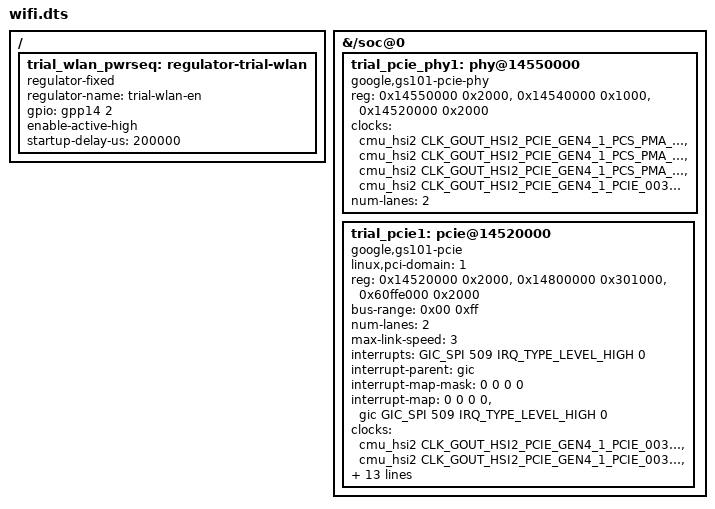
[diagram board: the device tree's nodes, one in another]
// SPDX-License-Identifier: GPL-2.0-only
// PCIe1 enumeration trial; reboot-only DT lifetime, no WiFi endpoint driver.
// Derived from M8 commit850061c7 and checked against stock CP1A.260305.018.
/dts-v1/;
/plugin/;
#include <dt-bindings/gpio/gpio.h>
#include <dt-bindings/interrupt-controller/arm-gic.h>
#include <dt-bindings/clock/google,gs101.h>
/ {
  fragment@0 {
    target-path = "/";
    __overlay__ {
      trial_wlan_pwrseq: regulator-trial-wlan {
        compatible = "regulator-fixed";
        regulator-name = "trial-wlan-en";
        gpio = <&gpp14 2 GPIO_ACTIVE_HIGH>;
        enable-active-high;
        startup-delay-us = <200000>;
        status = "okay";
      };
    };
  };
  fragment@1 {
    target-path = "/soc@0";
    __overlay__ {
      #address-cells = <1>;
      #size-cells = <1>;
      /* Preserve the base mapping; add only the WiFi outbound/config window. */
      ranges = <0x0 0x0 0x0 0x40000000>,
               <0x60000000 0x0 0x60000000 0x01000000>;
trial_pcie_phy1: phy@14550000 {
			compatible = "google,gs101-pcie-phy";
			reg = <0x14550000 0x2000>,
			      <0x14540000 0x1000>,
			      <0x14520000 0x2000>;
			reg-names = "phy", "pcs", "elbi";
			clocks = <&cmu_hsi2 CLK_GOUT_HSI2_PCIE_GEN4_1_PCS_PMA_PIPE_PAL_PCIE_I_APB_PCLK>,
				 <&cmu_hsi2 CLK_GOUT_HSI2_PCIE_GEN4_1_PCS_PMA_PCIEPHY210X2_QCH_I_APB_PCLK>,
				 <&cmu_hsi2 CLK_GOUT_HSI2_PCIE_GEN4_1_PCS_PMA_PHY_UDBG_I_APB_PCLK>,
				 <&cmu_hsi2 CLK_GOUT_HSI2_PCIE_GEN4_1_PCIE_003_PHY_REFCLK_IN>;
			clock-names = "pipe_pal", "qch_tm", "udbg", "refclk";
			num-lanes = <2>;
			#phy-cells = <0>;
			status = "okay";
		};

trial_pcie1: pcie@14520000 {
			compatible = "google,gs101-pcie";
			linux,pci-domain = <1>;
			reg = <0x14520000 0x2000>,
			      <0x14800000 0x301000>,
			      <0x60ffe000 0x2000>;
			reg-names = "elbi", "dbi", "config";
			device_type = "pci";
			#address-cells = <3>;
			#size-cells = <2>;
			ranges = <0x82000000 0 0x60000000 0x60000000 0 0x00ff0000>;
			bus-range = <0x00 0xff>;
			num-lanes = <2>;
			max-link-speed = <3>;
			interrupts = <GIC_SPI 509 IRQ_TYPE_LEVEL_HIGH 0>;
			interrupt-names = "msi";
			interrupt-parent = <&gic>;

			/*
			 * Legacy INTx routing. Everything behind this port uses
			 * MSI, but without the map of_irq_parse_pci() has
			 * nothing to walk and refuses with -EINVAL on every
			 * bind. The vendor gives HSI2 a map and leaves HSI1
			 * without one, so the modem port keeps failing there
			 * too -- that is expected, not a gap.
			 */
			#interrupt-cells = <1>;
			interrupt-map-mask = <0 0 0 0>;
			interrupt-map = <0 0 0 0 &gic GIC_SPI 509
					 IRQ_TYPE_LEVEL_HIGH 0>;
			clocks = <&cmu_hsi2 CLK_GOUT_HSI2_PCIE_GEN4_1_PCIE_003_DBI_ACLK_UG>,
				 <&cmu_hsi2 CLK_GOUT_HSI2_PCIE_GEN4_1_PCIE_003_MSTR_ACLK_UG>,
				 <&cmu_hsi2 CLK_GOUT_HSI2_PCIE_GEN4_1_PCIE_003_SLV_ACLK_UG>,
				 <&cmu_hsi2 CLK_GOUT_HSI2_PCIE_GEN4_1_PCIE_003_I_DRIVER_APB_CLK>,
				 <&cmu_hsi2 CLK_GOUT_HSI2_PCIE_IA_GEN4A_1_I_CLK>,
				 <&cmu_hsi2 CLK_GOUT_HSI2_UASC_PCIE_GEN4A_DBI_1_ACLK>,
				 <&cmu_hsi2 CLK_GOUT_HSI2_UASC_PCIE_GEN4A_DBI_1_PCLK>,
				 <&cmu_hsi2 CLK_GOUT_HSI2_UASC_PCIE_GEN4A_SLV_1_ACLK>,
				 <&cmu_hsi2 CLK_GOUT_HSI2_UASC_PCIE_GEN4A_SLV_1_PCLK>;
			clock-names = "dbi", "mstr", "slv", "driver_apb", "ia",
				      "uasc_dbi_aclk", "uasc_dbi_pclk",
				      "uasc_slv_aclk", "uasc_slv_pclk";
			phys = <&trial_pcie_phy1>;
			phy-names = "pcie";
			reset-gpios = <&gph2 0 GPIO_ACTIVE_LOW>;
			vpcie-supply = <&trial_wlan_pwrseq>;
			pinctrl-names = "default";
			pinctrl-0 = <&pcie1_clkreq>, <&pcie1_perst>;
			samsung,pmu-syscon = <&pmu_system_controller>;
			samsung,pmu-offset = <0x3ec4>;
			status = "okay";
		};

    };
  };
};
